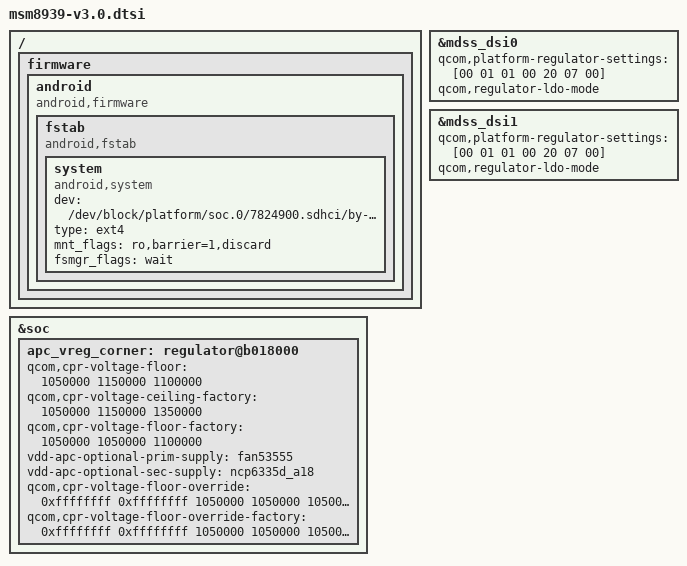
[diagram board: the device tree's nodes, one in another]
/*
 * Copyright (c) 2015, The Linux Foundation. All rights reserved.
 *
 * This program is free software; you can redistribute it and/or modify
 * it under the terms of the GNU General Public License version 2 and
 * only version 2 as published by the Free Software Foundation.
 *
 * This program is distributed in the hope that it will be useful,
 * but WITHOUT ANY WARRANTY; without even the implied warranty of
 * MERCHANTABILITY or FITNESS FOR A PARTICULAR PURPOSE.  See the
 * GNU General Public License for more details.
 */

/ {
	firmware: firmware {
		android {
			compatible = "android,firmware";
			fstab {
				compatible = "android,fstab";
				system {
					compatible = "android,system";
					dev = "/dev/block/platform/soc.0/7824900.sdhci/by-name/system";
					type = "ext4";
					mnt_flags = "ro,barrier=1,discard";
					fsmgr_flags = "wait";
					status = "ok";
				};
			};
		};
	};
};

&soc {
	apc_vreg_corner: regulator@b018000 {
		qcom,cpr-voltage-floor = <1050000 1150000 1100000>;
		qcom,cpr-voltage-ceiling-factory = <1050000 1150000 1350000>;
		qcom,cpr-voltage-floor-factory = <1050000 1050000 1100000>;
		vdd-apc-optional-prim-supply = <&fan53555>;
		vdd-apc-optional-sec-supply = <&ncp6335d_a18>;
		qcom,cpr-voltage-floor-override =
			<0xffffffff 0xffffffff 1050000 1050000 1050000 1150000
			1150000 1150000 1150000 1150000 1150000 1150000 1150000
			1150000 1150000 1150000 1100000 1100000 1100000 1100000
			1100000 1100000 1100000 1100000 1100000 1100000 1100000
			1100000 1100000 1100000>;
		qcom,cpr-voltage-floor-override-factory =
			<0xffffffff 0xffffffff 1050000 1050000 1050000 1050000
			1050000 1050000 1050000 1050000 1050000 1050000 1050000
			1050000 1050000 1100000 1100000 1100000 1100000 1100000
			1100000 1100000 1100000 1100000 1100000 1100000 1100000
			1100000 1100000 1100000>;
	};
};

&mdss_dsi0 {
	qcom,platform-regulator-settings = [00 01 01 00 20 07 00];
	qcom,regulator-ldo-mode;
};

&mdss_dsi1 {
	qcom,platform-regulator-settings = [00 01 01 00 20 07 00];
	qcom,regulator-ldo-mode;
};
